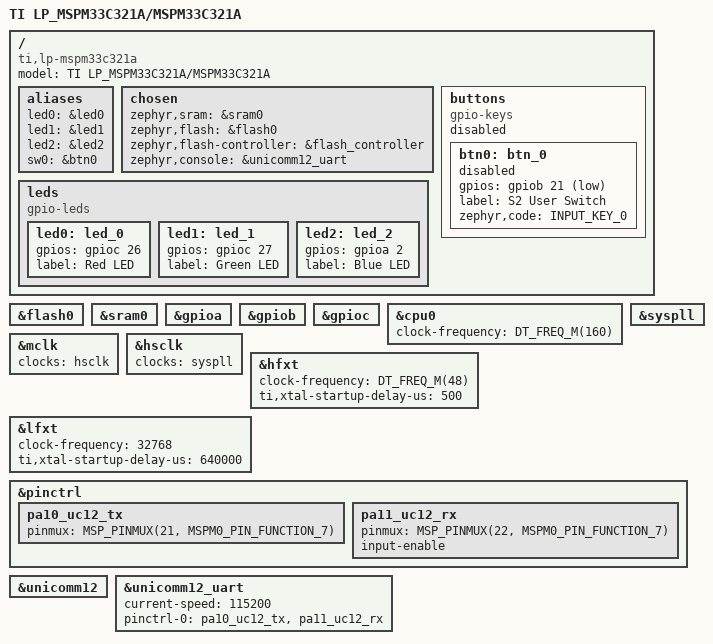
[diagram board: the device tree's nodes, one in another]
/*
 * Copyright (c) 2026 Texas Instruments
 * SPDX-License-Identifier: Apache-2.0
 */

/dts-v1/;

#include <ti/mspm33c/mspm33c321a.dtsi>
#include <ti/mspm33/c/mspm33c321a-pinctrl.dtsi>
#include <zephyr/dt-bindings/gpio/gpio.h>
#include <zephyr/dt-bindings/input/input-event-codes.h>

/ {
	model = "TI LP_MSPM33C321A/MSPM33C321A";
	compatible = "ti,lp-mspm33c321a";

	aliases {
		led0 = &led0;
		led1 = &led1;
		led2 = &led2;
		sw0 = &btn0;
	};

	chosen {
		zephyr,sram = &sram0;
		zephyr,flash = &flash0;
		zephyr,flash-controller = &flash_controller;
		zephyr,console = &unicomm12_uart;
	};

	leds {
		compatible = "gpio-leds";

		led0: led_0 {
			gpios = <&gpioc 26 GPIO_ACTIVE_HIGH>;
			label = "Red LED";
		};

		led1: led_1 {
			gpios = <&gpioc 27 GPIO_ACTIVE_HIGH>;
			label = "Green LED";
		};

		led2: led_2 {
			gpios = <&gpioa 2 GPIO_ACTIVE_HIGH>;
			label = "Blue LED";
		};
	};

	buttons {
		compatible = "gpio-keys";
		status = "disabled";

		/* S2 onboard user switch; verify polarity against board schematic */
		btn0: btn_0 {
			gpios = <&gpiob 21 (GPIO_ACTIVE_LOW | GPIO_PULL_UP)>;
			label = "S2 User Switch";
			zephyr,code = <INPUT_KEY_0>;
			status = "disabled";
		};
	};
};

&flash0 {
	status = "okay";
};

&sram0 {
	status = "okay";
};

&gpioa { status = "okay"; };
&gpiob { status = "okay"; };
&gpioc { status = "okay"; };

&cpu0 {
	clock-frequency = <DT_FREQ_M(160)>;
};

&mclk {
	clocks = <&hsclk>;
};

&hsclk {
	clocks = <&syspll>;
	status = "okay";
};

&syspll {
	status = "okay";
};

&hfxt {
	clock-frequency = <DT_FREQ_M(48)>;
	ti,xtal-startup-delay-us = <500>;
};

&lfxt {
	clock-frequency = <32768>;
	ti,xtal-startup-delay-us = <640000>;
};

&pinctrl {
	pa10_uc12_tx: pa10_uc12_tx {
		pinmux = <MSP_PINMUX(21, MSPM0_PIN_FUNCTION_7)>;
	};

	pa11_uc12_rx: pa11_uc12_rx {
		pinmux = <MSP_PINMUX(22, MSPM0_PIN_FUNCTION_7)>;
		input-enable;
	};
};

&unicomm12 {
	status = "okay";
};

&unicomm12_uart {
	status = "okay";
	current-speed = <115200>;

	pinctrl-0 = <&pa10_uc12_tx &pa11_uc12_rx>;
	pinctrl-names = "default";
};
